AUTOSAR XML (schema 00046)
package /runnables
  sender receiver interface throttle_ctrl
    data throttle_cmd: type=uint32
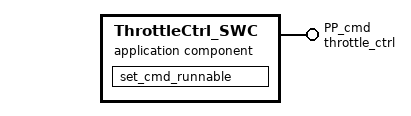
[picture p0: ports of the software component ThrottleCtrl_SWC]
  application sw component type ThrottleCtrl_SWC
    provide port PP_cmd: provided-interface=throttle_ctrl
    behavior throttle_cntrl_behavior
      runnable set_cmd_runnable: symbol=set_cmd
        data-write-access:
          access cmd_data: accessed-variable=PP_cmd.throttle_cmd
